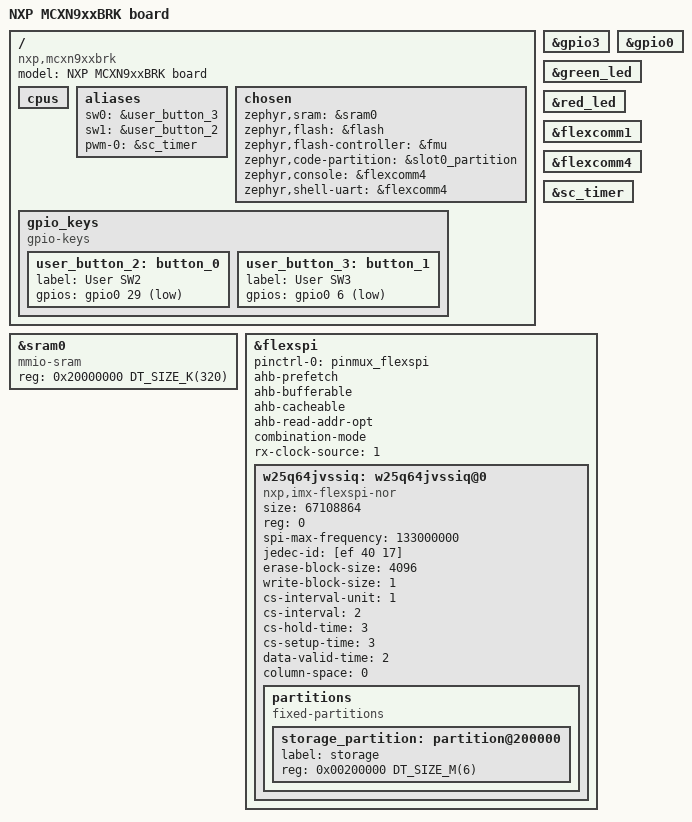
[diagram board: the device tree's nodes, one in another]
/*
 * Copyright 2023 NXP
 *
 * SPDX-License-Identifier: Apache-2.0
 */

/dts-v1/;

#include <nxp/nxp_mcxn94x.dtsi>
#include "mcxn9xxbrk_cm33.dtsi"

/ {
	model = "NXP MCXN9xxBRK board";
	compatible = "nxp,mcxn9xxbrk", "nxp,mcx";

	cpus {
		/delete-node/ cpu@1;
	};

	aliases{
		sw0 = &user_button_3;
		sw1 = &user_button_2;
		/* For pwm test suites */
		pwm-0 = &sc_timer;
	};

	chosen {
		zephyr,sram = &sram0;
		zephyr,flash = &flash;
		zephyr,flash-controller = &fmu;
		zephyr,code-partition = &slot0_partition;
		zephyr,console = &flexcomm4;
		zephyr,shell-uart = &flexcomm4;
	};

	gpio_keys {
		compatible = "gpio-keys";
		user_button_2: button_0 {
			label = "User SW2";
			gpios = <&gpio0 29 (GPIO_ACTIVE_LOW | GPIO_PULL_UP)>;
		};
		user_button_3: button_1 {
			label = "User SW3";
			gpios = <&gpio0 6 (GPIO_ACTIVE_LOW | GPIO_PULL_UP)>;
		};
	};
};

/*
 * Default for this board is to allocate SRAM0-5 to cpu0 but the
 * application can have an application specific device tree to
 * allocate the SRAM0-7 differently.
 *
 * For example, SRAM0-6 could be allocated to cpu0 with only SRAM7
 * for cpu1. This would require the value of sram0 to have a DT_SIZE_K
 * of 384. You would have to make updates to cpu1 sram settings as well.
 */
&sram0 {
	compatible = "mmio-sram";
	reg = <0x20000000 DT_SIZE_K(320)>;
};

&gpio3 {
	status = "okay";
};

&gpio0 {
	status = "okay";
};

&green_led {
	status = "okay";
};

&red_led {
	status = "okay";
};

&flexcomm1 {
	status = "okay";
};

&flexcomm4 {
	status = "okay";
};

&sc_timer {
	status = "okay";
};

&flexspi {
	status = "okay";
	pinctrl-0 = <&pinmux_flexspi>;
	pinctrl-names = "default";
	ahb-prefetch;
	ahb-bufferable;
	ahb-cacheable;
	ahb-read-addr-opt;
	combination-mode;
	rx-clock-source = <1>;

	/* WINBOND flash memory*/
	w25q64jvssiq: w25q64jvssiq@0 {
		compatible = "nxp,imx-flexspi-nor";
		size = <67108864>;
		reg = <0>;
		spi-max-frequency = <133000000>;
		status = "okay";
		jedec-id = [ef 40 17];
		erase-block-size = <4096>;
		write-block-size = <1>;
		cs-interval-unit = <1>;
		cs-interval = <2>;
		cs-hold-time = <3>;
		cs-setup-time = <3>;
		data-valid-time = <2>;
		column-space = <0>;
		partitions {
			compatible = "fixed-partitions";
			#address-cells = <1>;
			#size-cells = <1>;
			/* Reserve 2MB for Bootloader, use 6MB */
			storage_partition: partition@200000 {
				label = "storage";
				reg = <0x00200000 DT_SIZE_M(6)>;
			};
		};
	};
};
